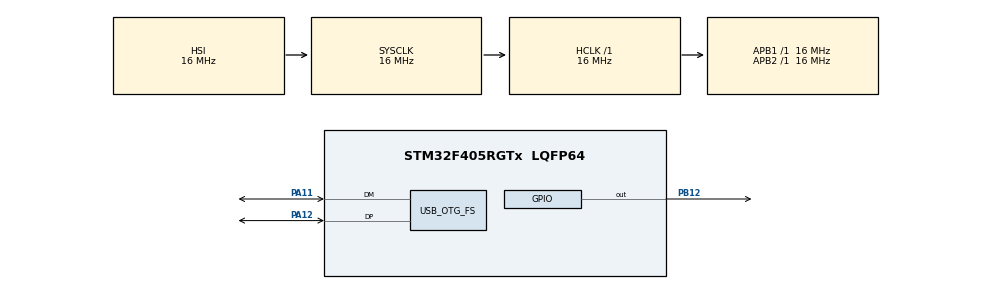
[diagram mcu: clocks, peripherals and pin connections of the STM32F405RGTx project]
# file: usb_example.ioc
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Mcu.Family=STM32F4
Mcu.Name=STM32F405RGTx
Mcu.Package=LQFP64
NVIC.OTG_FS_IRQn=true\:0\:0\:false\:false\:true\:false\:true
NVIC.PriorityGroup=NVIC_PRIORITYGROUP_4
PA11.Mode=Device_Only
PA11.Signal=USB_OTG_FS_DM
PA12.Mode=Device_Only
PA12.Signal=USB_OTG_FS_DP
PA13.Mode=Serial_Wire
PA13.Signal=SYS_JTMS-SWDIO
PA14.Mode=Serial_Wire
PA14.Signal=SYS_JTCK-SWCLK
PB12.Signal=GPIO_Output
PH0-OSC_IN.Mode=HSE-External-Oscillator
PH0-OSC_IN.Signal=RCC_OSC_IN
PH1-OSC_OUT.Mode=HSE-External-Oscillator
PH1-OSC_OUT.Signal=RCC_OSC_OUT
ProjectManager.HeapSize=0x200
ProjectManager.StackSize=0x400
ProjectManager.TargetToolchain=STM32CubeIDE
RCC.48MHZClocksFreq_Value=48000000
RCC.AHBFreq_Value=16000000
RCC.APB1Freq_Value=16000000
RCC.APB2Freq_Value=16000000
RCC.CortexFreq_Value=16000000
RCC.HSE_VALUE=8000000
RCC.HSI_VALUE=16000000
RCC.PLLM=4
RCC.PLLN=72
RCC.PLLQ=3
RCC.SYSCLKFreq_VALUE=16000000
RCC.VCOOutputFreq_Value=144000000
USB_DEVICE.CLASS_NAME_FS=HID
USB_DEVICE.PRODUCT_STRING_HID_FS=Knowledge Hub Keyboard
USB_DEVICE.VirtualMode-HID_FS=Hid
USB_DEVICE.VirtualModeFS=Hid_FS
USB_OTG_FS.VirtualMode=Device_Only
VP_USB_DEVICE_VS_USB_DEVICE_HID_FS.Mode=HID_FS
board=custom

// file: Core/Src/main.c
/* USER CODE BEGIN Header */
/**
  ******************************************************************************
  * @file           : main.c
  * @brief          : Main program body
  ******************************************************************************
  * @attention
  *
  * <h2><center>&copy; Copyright (c) 2021 STMicroelectronics.
  * All rights reserved.</center></h2>
  *
  * This software component is licensed by ST under BSD 3-Clause license,
  * the "License"; You may not use this file except in compliance with the
  * License. You may obtain a copy of the License at:
  *                        opensource.org/licenses/BSD-3-Clause
  *
  ******************************************************************************
  */
/* USER CODE END Header */
#include "main.h"
#include "usb_device.h"
#include "usbd_hid.h"

/* USER CODE BEGIN PV */
extern USBD_HandleTypeDef hUsbDeviceFS;

typedef struct
{
	uint8_t MODIFIER;
	uint8_t RESERVED;
	uint8_t KEYCODE1;
	uint8_t KEYCODE2;
	uint8_t KEYCODE3;
	uint8_t KEYCODE4;
	uint8_t KEYCODE5;
	uint8_t KEYCODE6;
}subKeyBoard;

uint8_t keyBoardHIDsub[] = {0,0,0,0,0,0,0,0};
/* USER CODE END PV */
void send_word(uint8_t num, uint8_t ctrl)
{
	if (ctrl)
	{
	  keyBoardHIDsub[0]=0x01;  // To press shift key<br>
	}
	  keyBoardHIDsub[2]=num;  // Press  key
	  USBD_HID_SendReport(&hUsbDeviceFS,keyBoardHIDsub,sizeof(keyBoardHIDsub));
	  HAL_Delay(50); 		       // Press all key for 50 milliseconds
	  keyBoardHIDsub[0]=0x00;  // To unpress ctrl key<br>
	  keyBoardHIDsub[2]=0x00;  // unPress key
	  USBD_HID_SendReport(&hUsbDeviceFS,keyBoardHIDsub,sizeof(keyBoardHIDsub));
	  HAL_Delay(400); 	       // Repeat this task on every 1 second
}
void SystemClock_Config(void);
static void MX_GPIO_Init(void);

typedef enum pos_button_e
{
	  button_push,
	  button_free
}pos_button_t;
int main(void)
{

  /* MCU Configuration--------------------------------------------------------*/

  /* Reset of all peripherals, Initializes the Flash interface and the Systick. */
  HAL_Init();

  /* Configure the system clock */
  SystemClock_Config();

  /* Initialize all configured peripherals */
  MX_GPIO_Init();
  MX_USB_DEVICE_Init();
  pos_button_t button_position = HAL_GPIO_ReadPin(GPIOA, 0) ? button_push : button_free;
  uint8_t was_done_copy = 0;
  uint8_t counter;

  /* Infinite loop */
  /* USER CODE BEGIN WHILE */
  while (1)
  {
	  if (button_position == button_push && counter > 10)
	 	  counter = (GPIOA->IDR & 1) ? 255 : counter - 1;
	   else if (button_position == button_free && counter < 240)
	   	  counter = (GPIOA->IDR & 1) ? 0 : counter + 1;
	   else if (button_position == button_push && counter <= 10)
	   {
	 	  	  button_position = button_free;
	 	  	  counter = 0;
	 	  	  // Если уже нажали ctrl+c, то жмём ctrl+v
	 	  	  if (was_done_copy)
	 	  		  send_word(0x19, 1);
	 	  	  else
	 	  		  send_word(0x06, 1);
	 	  	  //меняем значение
	 	  	  was_done_copy ^= 1;

	   }
	   else if (button_position == button_free && counter >= 240)
	   {
	 	  	  button_position = button_push;
	 	  	  counter = 255;
	   }	       // Repeat this task on every 1 second
  }
  /* USER CODE END 3 */
}

void SystemClock_Config(void)
{
  RCC_OscInitTypeDef RCC_OscInitStruct = {0};
  RCC_ClkInitTypeDef RCC_ClkInitStruct = {0};

  /** Configure the main internal regulator output voltage
  */
  __HAL_RCC_PWR_CLK_ENABLE();
  __HAL_PWR_VOLTAGESCALING_CONFIG(PWR_REGULATOR_VOLTAGE_SCALE1);
  /** Initializes the RCC Oscillators according to the specified parameters
  * in the RCC_OscInitTypeDef structure.
  */
  RCC_OscInitStruct.OscillatorType = RCC_OSCILLATORTYPE_HSI|RCC_OSCILLATORTYPE_HSE;
  RCC_OscInitStruct.HSEState = RCC_HSE_ON;
  RCC_OscInitStruct.HSIState = RCC_HSI_ON;
  RCC_OscInitStruct.HSICalibrationValue = RCC_HSICALIBRATION_DEFAULT;
  RCC_OscInitStruct.PLL.PLLState = RCC_PLL_ON;
  RCC_OscInitStruct.PLL.PLLSource = RCC_PLLSOURCE_HSE;
  RCC_OscInitStruct.PLL.PLLM = 4;
  RCC_OscInitStruct.PLL.PLLN = 72;
  RCC_OscInitStruct.PLL.PLLP = RCC_PLLP_DIV2;
  RCC_OscInitStruct.PLL.PLLQ = 3;
  if (HAL_RCC_OscConfig(&RCC_OscInitStruct) != HAL_OK)
  {
    Error_Handler();
  }
  /** Initializes the CPU, AHB and APB buses clocks
  */
  RCC_ClkInitStruct.ClockType = RCC_CLOCKTYPE_HCLK|RCC_CLOCKTYPE_SYSCLK
                              |RCC_CLOCKTYPE_PCLK1|RCC_CLOCKTYPE_PCLK2;
  RCC_ClkInitStruct.SYSCLKSource = RCC_SYSCLKSOURCE_HSI;
  RCC_ClkInitStruct.AHBCLKDivider = RCC_SYSCLK_DIV1;
  RCC_ClkInitStruct.APB1CLKDivider = RCC_HCLK_DIV1;
  RCC_ClkInitStruct.APB2CLKDivider = RCC_HCLK_DIV1;

  if (HAL_RCC_ClockConfig(&RCC_ClkInitStruct, FLASH_LATENCY_0) != HAL_OK)
  {
    Error_Handler();
  }
}

static void MX_GPIO_Init(void)
{
  GPIO_InitTypeDef GPIO_InitStruct = {0};

  /* GPIO Ports Clock Enable */
  __HAL_RCC_GPIOH_CLK_ENABLE();
  __HAL_RCC_GPIOB_CLK_ENABLE();
  __HAL_RCC_GPIOA_CLK_ENABLE();

  /*Configure GPIO pin Output Level */
  HAL_GPIO_WritePin(GPIOB, GPIO_PIN_12, GPIO_PIN_RESET);

  /*Configure GPIO pin : PB12 */
  GPIO_InitStruct.Pin = GPIO_PIN_12;
  GPIO_InitStruct.Mode = GPIO_MODE_OUTPUT_PP;
  GPIO_InitStruct.Pull = GPIO_NOPULL;
  GPIO_InitStruct.Speed = GPIO_SPEED_FREQ_LOW;
  HAL_GPIO_Init(GPIOB, &GPIO_InitStruct);

  GPIO_InitTypeDef GPIO_InitStruct_PA0 = {0};
  GPIO_InitStruct.Pin = GPIO_PIN_0;
  GPIO_InitStruct.Mode = GPIO_MODE_INPUT;
  GPIO_InitStruct.Pull = GPIO_NOPULL;
  GPIO_InitStruct.Speed = GPIO_SPEED_FREQ_LOW;
  HAL_GPIO_Init(GPIOA, &GPIO_InitStruct_PA0);
}

void Error_Handler(void)
{
  __disable_irq();
  while (1)
  {
  }
}

/************************ (C) COPYRIGHT STMicroelectronics *****END OF FILE****/
